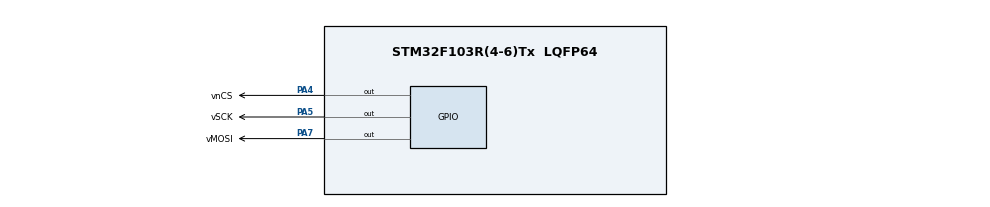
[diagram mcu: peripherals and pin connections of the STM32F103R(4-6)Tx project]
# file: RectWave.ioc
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Mcu.Family=STM32F1
Mcu.Name=STM32F103R(4-6)Tx
Mcu.Package=LQFP64
NVIC.PriorityGroup=NVIC_PRIORITYGROUP_4
PA4.GPIO_Label=vnCS
PA4.GPIO_PuPd=GPIO_PULLDOWN
PA4.Signal=GPIO_Output
PA5.GPIO_Label=vSCK
PA5.GPIO_ModeDefaultOutputPP=GPIO_MODE_OUTPUT_OD
PA5.GPIO_PuPd=GPIO_PULLUP
PA5.GPIO_Speed=GPIO_SPEED_FREQ_HIGH
PA5.PinState=GPIO_PIN_SET
PA5.Signal=GPIO_Output
PA7.GPIO_Label=vMOSI
PA7.GPIO_ModeDefaultOutputPP=GPIO_MODE_OUTPUT_OD
PA7.GPIO_PuPd=GPIO_PULLUP
PA7.GPIO_Speed=GPIO_SPEED_FREQ_HIGH
PA7.PinState=GPIO_PIN_SET
PA7.Signal=GPIO_Output
ProjectManager.HeapSize=0x200
ProjectManager.StackSize=0x400
ProjectManager.TargetToolchain=MDK-ARM V5.32
RCC.APB1Freq_Value=8000000
RCC.APB2Freq_Value=8000000
VP_SYS_VS_ND.Mode=No_Debug
board=custom

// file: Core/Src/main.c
/* USER CODE BEGIN Header */
/**
  ******************************************************************************
  * @file           : main.c
  * @brief          : Main program body
  ******************************************************************************
  * @attention
  *
  * Copyright (c) 2022 STMicroelectronics.
  * All rights reserved.
  *
  * This software is licensed under terms that can be found in the LICENSE file
  * in the root directory of this software component.
  * If no LICENSE file comes with this software, it is provided AS-IS.
  *
  ******************************************************************************
  */
/* USER CODE END Header */
#include "main.h"
#include "gpio.h"

/* USER CODE BEGIN Includes */
#include "vSPI.h"		//引入自定义头文件
#include "MCP4921.h"
/* USER CODE END Includes */

/* USER CODE BEGIN PV */
#define DAC_CMD_ACTIVE     0x30u
#define DAC_LOW_CODE       0x000u
#define DAC_FULL_CODE      0x0fffu
#define AMP_MIN_V          5u
#define AMP_MAX_V          20u
#define AMP_STEP_V         5u
#define FREQ_MULT_MIN      1u
#define FREQ_MULT_MAX      8u
#define KEY_DEBOUNCE_MS    180u
#define WAVE_PHASE_LIMIT   40u

static uint8_t g_freq_mult = 1u;
static uint8_t g_amp_set_v = 20u;
static uint8_t g_external_mode = 0u;
static uint8_t g_output_enabled = 1u;
static uint8_t g_wave_high = 0u;
static uint32_t g_last_wave_tick = 0u;
static uint32_t g_last_key_tick = 0u;
static uint32_t g_wave_phase = 0u;
static GPIO_PinState g_last_ext_trig = GPIO_PIN_RESET;
/* USER CODE END PV */

void SystemClock_Config(void);
/* USER CODE BEGIN PFP */
static uint16_t App_AmplitudeToDacCode(uint8_t amplitude_v);
static uint8_t App_IsKeyPressed(GPIO_TypeDef *port, uint16_t pin);
static void App_ResetWaveTiming(uint32_t now);
static void App_WriteWaveLow(void);
static void App_WriteWaveHigh(void);
static void App_ProcessKeys(void);
static void App_ProcessExternalTrigger(void);
static void App_ProcessWaveform(void);
/* USER CODE END PFP */

/* USER CODE BEGIN 0 */
static uint16_t App_AmplitudeToDacCode(uint8_t amplitude_v)
{
  if (amplitude_v < AMP_MIN_V)
  {
    amplitude_v = AMP_MIN_V;
  }
  if (amplitude_v > AMP_MAX_V)
  {
    amplitude_v = AMP_MAX_V;
  }

  return (uint16_t)(((uint32_t)amplitude_v * DAC_FULL_CODE) / AMP_MAX_V);
}

static uint8_t App_IsKeyPressed(GPIO_TypeDef *port, uint16_t pin)
{
  return (HAL_GPIO_ReadPin(port, pin) == GPIO_PIN_RESET) ? 1u : 0u;
}

static void App_ResetWaveTiming(uint32_t now)
{
  g_last_wave_tick = now;
  g_wave_phase = 0u;
}

static void App_WriteWaveLow(void)
{
  MCP4921Write(DAC_CMD_ACTIVE, DAC_LOW_CODE);
  HAL_GPIO_WritePin(WAVE_MARK_GPIO_Port, WAVE_MARK_Pin, GPIO_PIN_RESET);
  g_wave_high = 0u;
}

static void App_WriteWaveHigh(void)
{
  MCP4921Write(DAC_CMD_ACTIVE, App_AmplitudeToDacCode(g_amp_set_v));
  HAL_GPIO_WritePin(WAVE_MARK_GPIO_Port, WAVE_MARK_Pin, GPIO_PIN_SET);
  g_wave_high = 1u;
}

static void App_ProcessKeys(void)
{
  uint32_t now = HAL_GetTick();

  if ((now - g_last_key_tick) < KEY_DEBOUNCE_MS)
  {
    return;
  }

  if (App_IsKeyPressed(KEY_FREQ_GPIO_Port, KEY_FREQ_Pin) != 0u)
  {
    g_freq_mult++;
    if (g_freq_mult > FREQ_MULT_MAX)
    {
      g_freq_mult = FREQ_MULT_MIN;
    }
    App_ResetWaveTiming(now);
    g_last_key_tick = now;
  }
  else if (App_IsKeyPressed(KEY_AMP_UP_GPIO_Port, KEY_AMP_UP_Pin) != 0u)
  {
    if (g_amp_set_v < AMP_MAX_V)
    {
      g_amp_set_v += AMP_STEP_V;
      if (g_wave_high != 0u)
      {
        App_WriteWaveHigh();
      }
    }
    g_last_key_tick = now;
  }
  else if (App_IsKeyPressed(KEY_AMP_DOWN_GPIO_Port, KEY_AMP_DOWN_Pin) != 0u)
  {
    if (g_amp_set_v > AMP_MIN_V)
    {
      g_amp_set_v -= AMP_STEP_V;
      if (g_wave_high != 0u)
      {
        App_WriteWaveHigh();
      }
    }
    g_last_key_tick = now;
  }
  else if (App_IsKeyPressed(KEY_MODE_GPIO_Port, KEY_MODE_Pin) != 0u)
  {
    g_external_mode ^= 1u;
    g_output_enabled = (g_external_mode == 0u) ? 1u : 0u;
    App_ResetWaveTiming(now);
    App_WriteWaveLow();
    g_last_key_tick = now;
  }
}

static void App_ProcessExternalTrigger(void)
{
  GPIO_PinState now_state = HAL_GPIO_ReadPin(EXT_TRIG_GPIO_Port, EXT_TRIG_Pin);

  if (g_external_mode != 0u)
  {
    if ((g_last_ext_trig == GPIO_PIN_RESET) && (now_state == GPIO_PIN_SET))
    {
      g_output_enabled = 1u;
      App_ResetWaveTiming(HAL_GetTick());
      App_WriteWaveHigh();
    }
  }

  g_last_ext_trig = now_state;
}

static void App_ProcessWaveform(void)
{
  uint32_t now = HAL_GetTick();
  uint32_t elapsed_ms = now - g_last_wave_tick;

  if (g_output_enabled == 0u)
  {
    App_WriteWaveLow();
    App_ResetWaveTiming(now);
    return;
  }

  if (elapsed_ms == 0u)
  {
    return;
  }

  g_last_wave_tick = now;
  g_wave_phase += elapsed_ms * g_freq_mult;

  while (g_wave_phase >= WAVE_PHASE_LIMIT)
  {
    g_wave_phase -= WAVE_PHASE_LIMIT;
    if (g_wave_high != 0u)
    {
      App_WriteWaveLow();
    }
    else
    {
      App_WriteWaveHigh();
    }
  }
}

/* USER CODE END 0 */

int main(void)
{

  /* MCU Configuration--------------------------------------------------------*/

  /* Reset of all peripherals, Initializes the Flash interface and the Systick. */
  HAL_Init();

  /* Configure the system clock */
  SystemClock_Config();

  /* Initialize all configured peripherals */
  MX_GPIO_Init();
  /* USER CODE BEGIN 2 */
  App_WriteWaveLow();
  App_ResetWaveTiming(HAL_GetTick());
  /* USER CODE END 2 */

  /* Infinite loop */
  /* USER CODE BEGIN WHILE */
  while (1)
  {
    App_ProcessKeys();
    App_ProcessExternalTrigger();
    App_ProcessWaveform();
    HAL_Delay(1);
    /* USER CODE END WHILE */

  }
}

void SystemClock_Config(void)
{
  RCC_OscInitTypeDef RCC_OscInitStruct = {0};
  RCC_ClkInitTypeDef RCC_ClkInitStruct = {0};

  /** Initializes the RCC Oscillators according to the specified parameters
  * in the RCC_OscInitTypeDef structure.
  */
  RCC_OscInitStruct.OscillatorType = RCC_OSCILLATORTYPE_HSI;
  RCC_OscInitStruct.HSIState = RCC_HSI_ON;
  RCC_OscInitStruct.HSICalibrationValue = RCC_HSICALIBRATION_DEFAULT;
  RCC_OscInitStruct.PLL.PLLState = RCC_PLL_NONE;
  if (HAL_RCC_OscConfig(&RCC_OscInitStruct) != HAL_OK)
  {
    Error_Handler();
  }

  /** Initializes the CPU, AHB and APB buses clocks
  */
  RCC_ClkInitStruct.ClockType = RCC_CLOCKTYPE_HCLK|RCC_CLOCKTYPE_SYSCLK
                              |RCC_CLOCKTYPE_PCLK1|RCC_CLOCKTYPE_PCLK2;
  RCC_ClkInitStruct.SYSCLKSource = RCC_SYSCLKSOURCE_HSI;
  RCC_ClkInitStruct.AHBCLKDivider = RCC_SYSCLK_DIV1;
  RCC_ClkInitStruct.APB1CLKDivider = RCC_HCLK_DIV1;
  RCC_ClkInitStruct.APB2CLKDivider = RCC_HCLK_DIV1;

  if (HAL_RCC_ClockConfig(&RCC_ClkInitStruct, FLASH_LATENCY_0) != HAL_OK)
  {
    Error_Handler();
  }
}

void Error_Handler(void)
{
  __disable_irq();
  while (1)
  {
  }
}
